# GD32F1x0 register map
File version: 1.0
CPU: CM3 r2p1, little endian, no MPU, no FPU, 4 interrupt priority bits
Registers are 32-bit, read-write, reset 0x0 unless marked. A register's access mark holds for its fields unless they carry their own. Offsets are from the block's base; [hi:lo] are bit positions; {n}, {i} and the like mark numbered series.

## OPA_IVREF
Base 0x40007C00
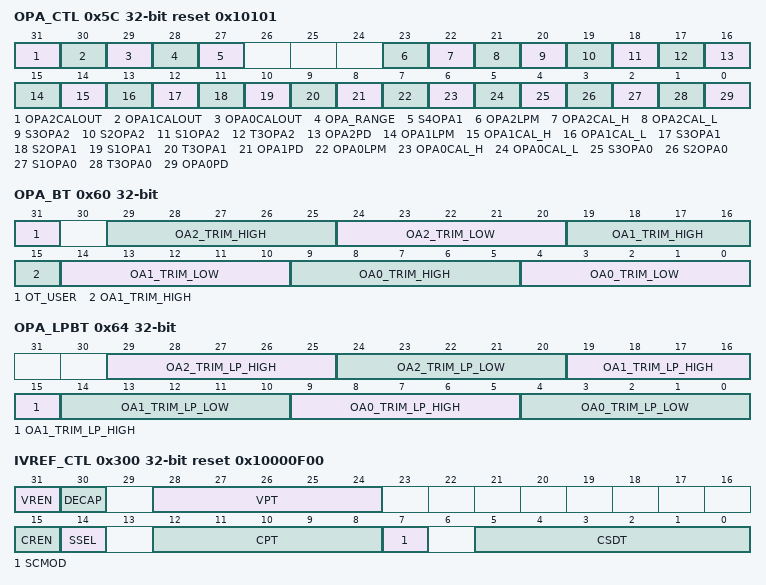
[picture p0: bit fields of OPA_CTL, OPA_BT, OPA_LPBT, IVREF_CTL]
0x5C OPA_CTL access per field reset 0x10101 — OPA control register
  [31] OPA2CALOUT ro — OPA2 calibration output
  [30] OPA1CALOUT ro — OPA1 calibration output
  [29] OPA0CALOUT ro — OPA0 calibration output
  [28] OPA_RANGE rw — Power supply range
  [27] S4OPA1 rw — S4 switch enable for OPA1
  [23] OPA2LPM rw — OPA2 low power mode
  [22] OPA2CAL_H rw — OPA2 offset calibration for N diff
  [21] OPA2CAL_L rw — OPA2 offset calibration for P diff
  [20] S3OPA2 rw — S3 switch enable for OPA2
  [19] S2OPA2 rw — S2 switch enable for OPA2
  [18] S1OPA2 rw — S1 switch enable for OPA2
  [17] T3OPA2 rw — T3 switch enable for OPA2
  [16] OPA2PD rw — OPA2 power down
  [15] OPA1LPM rw — OPA1 low power mode
  [14] OPA1CAL_H rw — OPA1 offset calibration for N diff
  [13] OPA1CAL_L rw — OPA1 offset calibration for P diff
  [12] S3OPA1 rw — S3 switch enable for OPA1
  [11] S2OPA1 rw — S2 switch enable for OPA1
  [10] S1OPA1 rw — S1 switch enable for OPA1
  [9] T3OPA1 rw — T3 switch enable for OPA1
  [8] OPA1PD rw — OPA1 power down
  [7] OPA0LPM rw — OPA0 low power mode
  [6] OPA0CAL_H rw — OPA0 offset calibration for N diff
  [5] OPA0CAL_L rw — OPA0 offset calibration for P diff
  [4] S3OPA0 rw — S3 switch enable for OPA0
  [3] S2OPA0 rw — S2 switch enable for OPA0
  [2] S1OPA0 rw — S1 switch enable for OPA0
  [1] T3OPA0 rw — T3 switch enable for OPA0
  [0] OPA0PD rw — OPA0 power down
0x60 OPA_BT access per field — OPA offset trimming for normal mode register
  [31] OT_USER wo — user programmed trimming value
  [29:25] OA2_TRIM_HIGH rw — OPA2, normal mode 5-bit offset trim value for NMOS pairs
  [24:20] OA2_TRIM_LOW rw — OPA2, normal mode 5-bit offset trim value for PMOS pairs
  [19:15] OA1_TRIM_HIGH rw — OPA1, normal mode 5-bit offset trim value for NMOS pairs
  [14:10] OA1_TRIM_LOW rw — OPA1, normal mode 5-bit offset trim value for PMOS pairs
  [9:5] OA0_TRIM_HIGH rw — OPA0, normal mode 5-bit offset trim value for NMOS pairs
  [4:0] OA0_TRIM_LOW rw — OPA0, normal mode 5-bit offset trim value for PMOS pairs
0x64 OPA_LPBT — OPA offset trimming for low power mode register
  [29:25] OA2_TRIM_LP_HIGH — OPA2, low power mode 5-bit offset trim value for NMOS pairs
  [24:20] OA2_TRIM_LP_LOW — OPA2, low power mode 5-bit offset trim value for PMOS pairs
  [19:15] OA1_TRIM_LP_HIGH — OPA1, low power mode 5-bit offset trim value for NMOS pairs
  [14:10] OA1_TRIM_LP_LOW — OPA1, low power mode 5-bit offset trim value for PMOS pairs
  [9:5] OA0_TRIM_LP_HIGH — OPA0, low power mode 5-bit offset trim value for NMOS pairs
  [4:0] OA0_TRIM_LP_LOW — OPA0, low power mode 5-bit offset trim value for PMOS pairs
0x300 IVREF_CTL reset 0x10000F00 — IVREF control register
  [31] VREN — Voltage reference enable
  [30] DECAP — Disconnect external capacitor
  [28:24] VPT — Voltage precision tirm
  [15] CREN — Current reference enable
  [14] SSEL — Step selection
  [12:8] CPT — Current precision trim
  [7] SCMOD — Sink current mode
  [5:0] CSDT — Current step data

## PMU — Power management unit
Base 0x40007000
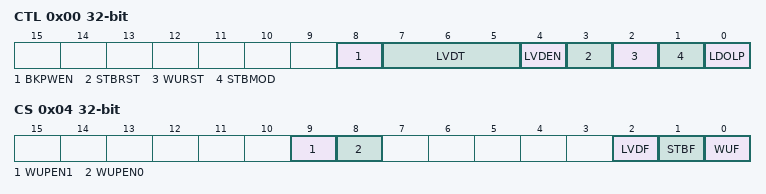
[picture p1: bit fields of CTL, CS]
0x00 CTL — power control register
  [8] BKPWEN — Backup Domain Write Enable
  [7:5] LVDT — Low Voltage Detector Threshold
  [4] LVDEN — Low Voltage Detector Enable
  [3] STBRST — Standby Flag Reset
  [2] WURST — Wakeup Flag Reset
  [1] STBMOD — Standby Mode
  [0] LDOLP — LDO Low Power Mode
0x04 CS access per field — power control/status register
  [9] WUPEN1 rw — WKUPN1 Pin Enable
  [8] WUPEN0 rw — Enable WKUP pin
  [2] LVDF ro — Low Voltage Detector Status Flag
  [1] STBF ro — Standby flag
  [0] WUF ro — Wakeup flag

## SLCD — Segment LCD controller
Base 0x40002400
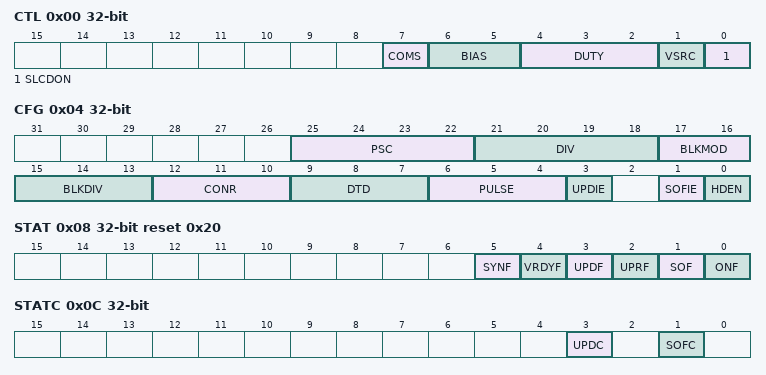
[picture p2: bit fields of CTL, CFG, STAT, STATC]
0x00 CTL — Control register
  [7] COMS — Common/segment padselect
  [6:5] BIAS — Bias select
  [4:2] DUTY — Duty select
  [1] VSRC — SLCD voltage source
  [0] SLCDON — SLCD controller start
0x04 CFG — SLCD configuration register
  [25:22] PSC — SLCD clock prescaler
  [21:18] DIV — SLCD clock divider
  [17:16] BLKMOD — Blink mode
  [15:13] BLKDIV — Blink frequency divider
  [12:10] CONR — Contrast ratio
  [9:7] DTD — Dead time duration
  [6:4] PULSE — Pulse on duration
  [3] UPDIE — SLCD update done interrupt enable
  [1] SOFIE — Start of frame interrupt enable
  [0] HDEN — High drive enable
0x08 STAT access per field reset 0x20 — SLCD status flag register
  [5] SYNF ro — SLCD_CFG register synchronization flag
  [4] VRDYF ro — SLCD voltage ready flag
  [3] UPDF ro — Update SLCD data done flag
  [2] UPRF rw — Update SLCD data request flag
  [1] SOF ro — Start of frame flag
  [0] ONF ro — SLCD controller on flag
0x0C STATC — SLCD status flag clear register
  [3] UPDC — SLCD data update done clear bit
  [1] SOFC — Start of frame flag clear
{0x14+8i} DATA{i} (i=0..7) — SLCD display data register
  [31:0] SEG_DATA{i} — Each bit corresponds to one segment to display
